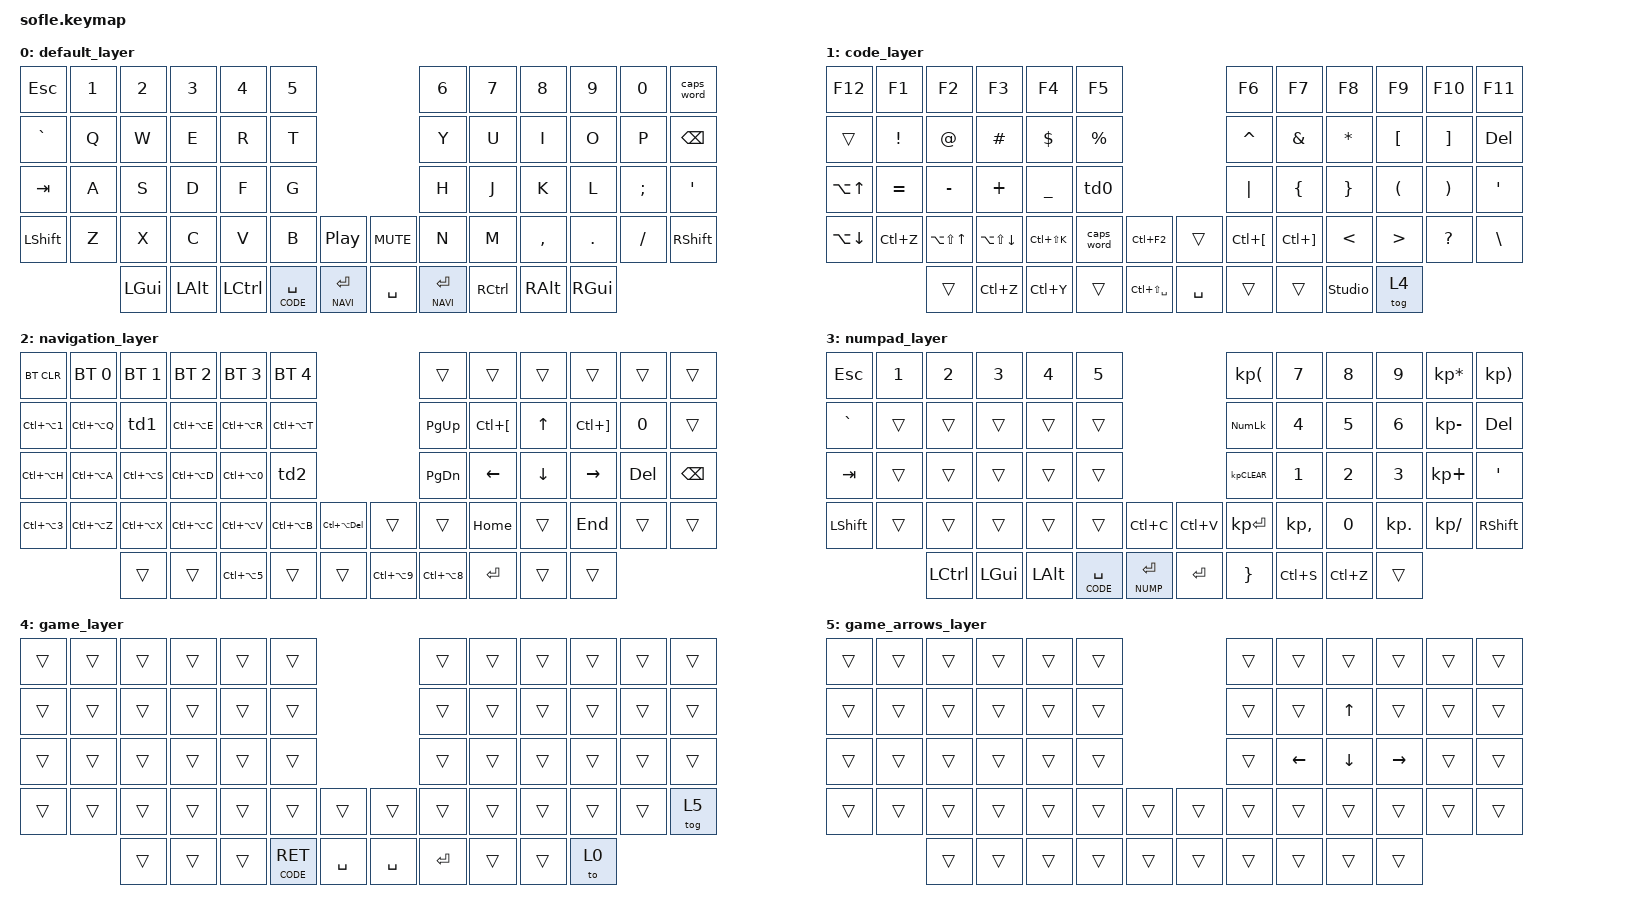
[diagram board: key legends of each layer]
/*
 * Copyright (c) 2020 The ZMK Contributors
 *
 * SPDX-License-Identifier: MIT
 */

#include <behaviors.dtsi>
#include <dt-bindings/zmk/keys.h>
#include <dt-bindings/zmk/bt.h>
#include <dt-bindings/zmk/ext_power.h>


&sensors {
  triggers-per-rotation = <48>;
};

#define DEFAULT 0
#define CODE 1
#define NAVI 2
#define NUMP 3
#define GAME 4
#define GAME_ARROWS 5



/ {
  behaviors {
    lht: layer_hold_tap {
        compatible = "zmk,behavior-hold-tap";
        #binding-cells = <2>;
        tapping-term-ms = <190>;
        flavor = "balanced";
        bindings = <&mo>, <&kp>;
        quick-tap-ms = <175>;
    };
    lhtog: layer_hold_tog {
        compatible = "zmk,behavior-hold-tap";
        #binding-cells = <2>;
        tapping-term-ms = <190>;
        flavor = "balanced";
        bindings = <&mo>, <&tog>;
        quick-tap-ms = <175>;
    };
    td0: tap_dance_0 {
      compatible = "zmk,behavior-tap-dance";
      #binding-cells = <0>;
      tapping-term-ms = <175>;
      bindings = <&kp DEL>, <&kp BSPC>;
    };
    td1: tap_dance_1 {
      compatible = "zmk,behavior-tap-dance";
      #binding-cells = <0>;
      tapping-term-ms = <175>;
      bindings = <&kp LC(LA(W))>, <&kp LG(UP)>, <&minimize_window>;
    };
    td2: tap_dance_2 {
      compatible = "zmk,behavior-tap-dance";
      #binding-cells = <0>;
      tapping-term-ms = <175>;
      bindings = <&kp LC(LA(G))>, <&kp LC(LA(A))>;
    };
    macros {
      minimize_window: minimize_window {
        compatible = "zmk,behavior-macro";
        #binding-cells = <0>;
        bindings
          = <&macro_press &kp LGUI>
          , <&macro_tap &kp DOWN &kp DOWN>
          , <&macro_release &kp LGUI>
          ;
      };
    };
  };

  keymap {
    compatible = "zmk,keymap";
		default_layer {
			bindings = <
				&kp ESC     &kp N1 	&kp N2   	&kp N3   &kp N4    &kp N5                      								&kp N6 				  &kp N7    &kp N8    &kp N9   &kp N0   &caps_word
				&kp GRAVE   &kp Q  	&kp W    	&kp E    &kp R     &kp T                       								&kp Y  				  &kp U     &kp I     &kp O    &kp P    &kp BSPC
				&kp TAB     &kp A  	&kp S    	&kp D    &kp F     &kp G                       								&kp H  	 			  &kp J     &kp K     &kp L    &kp SEMI &kp SQT
				&kp LSHFT   &kp Z  	&kp X    	&kp C    &kp V     &kp B  				 &kp C_PP  		  &kp C_MUTE  &kp N  	 			  &kp M     &kp COMMA &kp DOT  &kp FSLH &kp RSHFT
														&kp LGUI  &kp LALT &kp LCTRL &lht CODE SPACE &lht NAVI RET  &kp SPACE   &lht NAVI RET 	&kp RCTRL &kp RALT  &kp RGUI
			>;

				sensor-bindings = <
					&inc_dec_kp C_NEXT C_PREV
					&inc_dec_kp C_VOL_UP C_VOL_DN
				>;
		};

		code_layer {
			bindings = <
				&kp F12     &kp F1    &kp F2          &kp F3            &kp F4    		&kp F5                   			          &kp F6    	  &kp F7   			    &kp F8   	      &kp F9    &kp F10   &kp F11
				&trans      &kp EXCL  &kp AT          &kp HASH          &kp DLLR  		&kp PRCNT               			          &kp CARET 	  &kp AMPS 			    &kp STAR 	      &kp LBKT  &kp RBKT  &kp DEL
				&kp LA(UP)  &kp EQUAL &kp MINUS       &kp PLUS          &kp UNDER 		&td0                 			              &kp PIPE  	  &kp LBRC 			    &kp RBRC 	      &kp LPAR  &kp RPAR  &kp SQT
				&kp LA(DOWN)&kp LC(Z) &kp LA(LS(UP))  &kp LA(LS(DOWN))  &kp LC(LS(K)) &caps_word  &kp LC(F2)        &trans 	  &kp LC(LBKT) 	&kp LC(RBKT) 	    &kp LT          &kp GT 	  &kp QMARK &kp BSLH
														  &trans          &kp LC(Z)         &kp LC(Y)     &trans      &kp LC(LS(SPACE)) &kp SPACE &trans        &trans            &studio_unlock  &tog 4
			>;

        sensor-bindings = <
          &inc_dec_kp C_VOL_UP C_VOL_DN 
          &inc_dec_kp PG_UP PG_DN
        >;
    };

		navigation_layer {
			bindings = <
				&bt BT_CLR 		  &bt BT_SEL 0 	&bt BT_SEL 1    &bt BT_SEL 2    &bt BT_SEL 3 	  &bt BT_SEL 4                                  &trans          &trans    		&trans   &trans    		&trans  &trans
				&kp LC(LA(N1))  &kp LC(LA(Q)) &td1            &kp LC(LA(E))   &kp LC(LA(R))   &kp LC(LA(T))                                 &kp PG_UP       &kp LC(LBKT)	&kp UP   &kp LC(RBKT)	&kp N0  &trans
				&kp LC(LA(H))   &kp LC(LA(A)) &kp LC(LA(S))   &kp LC(LA(D))   &kp LC(LA(N0))	&td2                                          &kp PG_DN       &kp LEFT  		&kp DOWN &kp RIGHT 		&kp DEL &kp BSPC
				&kp LC(LA(N3))  &kp LC(LA(Z)) &kp LC(LA(X))   &kp LC(LA(C))   &kp LC(LA(V))   &kp LC(LA(B)) &kp LC(LA(DEL)) &trans          &trans          &kp HOME  		&trans   &kp END   		&trans  &trans
																		  &trans          &trans          &kp LC(LA(N5))  &trans        &trans          &kp LC(LA(N9))  &kp LC(LA(N8))  &kp RET   		&trans   &trans
			>;

			sensor-bindings = <
				&inc_dec_kp C_VOL_UP C_VOL_DN 
				&inc_dec_kp LBKT RBKT
			>;
		};

    // Adds a numpad under the right hand while held.
    numpad_layer {
      bindings = <
        &kp ESC   &kp N1  &kp N2    &kp N3    &kp N4    &kp N5                     									&kp KP_LPAR  	&kp N7       	&kp N8    &kp N9     &kp KP_MULTIPLY &kp KP_RPAR
        &kp GRAVE &trans  &trans    &trans    &trans    &trans                     									&kp KP_NUM   	&kp N4       	&kp N5    &kp N6     &kp KP_MINUS    &kp DEL
        &kp TAB   &trans  &trans    &trans    &trans    &trans                     									&kp KP_CLEAR 	&kp N1       	&kp N2    &kp N3     &kp KP_PLUS     &kp SQT
        &kp LSHFT &trans  &trans    &trans    &trans    &trans 					&kp LC(C) 				&kp LC(V) &kp KP_ENTER 	&kp KP_COMMA 	&kp N0    &kp KP_DOT &kp KP_DIVIDE   &kp RSHFT
  												&kp LCTRL	&kp LGUI  &kp LALT	&lht CODE SPACE &lht NUMP RETURN	&kp RET  	&kp RBRC     	&kp LC(S) 		&kp LC(Z) &trans
      >;

      sensor-bindings = <
        &inc_dec_kp LC(LS(RIGHT)) LC(LS(LEFT)) 
        &inc_dec_kp LS(UP) LS(DOWN)
      >;
    };

    game_layer {
      bindings = <
        &trans  &trans  &trans  &trans  &trans  &trans                              &trans  &trans  &trans  &trans  &trans  &trans
        &trans  &trans  &trans  &trans  &trans  &trans                              &trans  &trans  &trans  &trans  &trans  &trans
        &trans  &trans  &trans  &trans  &trans  &trans                              &trans  &trans  &trans  &trans  &trans  &trans
        &trans  &trans  &trans  &trans  &trans  &trans          &trans    &trans    &trans  &trans  &trans  &trans  &trans  &tog 5
                        &trans  &trans  &trans  &lhtog CODE RET &kp SPACE &kp SPACE &kp RET &trans  &trans  &to 0
      >;

      sensor-bindings = <
        &inc_dec_kp C_NEXT C_PREV
        &inc_dec_kp C_VOL_UP C_VOL_DN 
      >;
    };
 
    game_arrows_layer {
      bindings = <
        &trans  &trans  &trans  &trans  &trans  &trans                          &trans  &trans    &trans    &trans    &trans  &trans
        &trans  &trans  &trans  &trans  &trans  &trans                          &trans  &trans    &kp UP    &trans    &trans  &trans
        &trans  &trans  &trans  &trans  &trans  &trans                          &trans  &kp LEFT  &kp DOWN  &kp RIGHT &trans  &trans
        &trans  &trans  &trans  &trans  &trans  &trans  &trans  &trans  &trans  &trans  &trans    &trans    &trans  &trans
                        &trans  &trans  &trans  &trans  &trans  &trans  &trans  &trans  &trans    &trans
      >;

      sensor-bindings = <
        &inc_dec_kp C_NEXT C_PREV
        &inc_dec_kp C_VOL_UP C_VOL_DN 
      >;
    };
 };
};
